# STM32C562 register map
File version: 2.1.0
CPU: CM33 r0p4, little endian, MPU, FPU, 4 interrupt priority bits
Registers are 32-bit, read-write, reset 0x0 unless marked. A register's access mark holds for its fields unless they carry their own. Offsets are from the block's base; [hi:lo] are bit positions; {n}, {i} and the like mark numbered series.

## ICACHE — ICACHE register block
Base 0x40030400
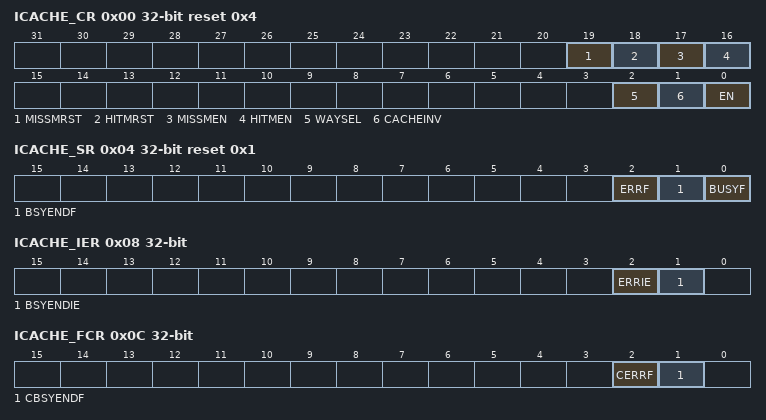
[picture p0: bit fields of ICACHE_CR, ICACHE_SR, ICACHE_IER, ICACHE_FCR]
0x00 ICACHE_CR reset 0x4 — ICACHE control register
  [19] MISSMRST — miss monitor reset
    0=release the cache miss monitor reset (needed to enable the counting); 1=reset cache miss monitor
  [18] HITMRST — hit monitor reset
    0=release the cache miss monitor reset (needed to enable the counting); 1=reset cache hit monitor
  [17] MISSMEN — miss monitor enable
    0=cache miss monitor switched off. Stopping the monitor does not reset it.; 1=cache miss monitor enabled
  [16] HITMEN — hit monitor enable
    0=cache hit monitor switched off. Stopping the monitor does not reset it.; 1=cache hit monitor enabled
  [2] WAYSEL — cache associativity mode selection
    0=direct mapped cache (1-way cache); 1=n-way set associative cache (reset value)
  [1] CACHEINV wo — cache invalidation
    0=no effect; 1=invalidate entire cache (all cache lines valid bit = 0)
  [0] EN — enable
    0=cache disabled; 1=cache enabled
0x04 ICACHE_SR ro reset 0x1 — ICACHE status register
  [2] ERRF — cache error flag
    0=no error; 1=an error occurred during the operation (cacheable write)
  [1] BSYENDF — busy end flag
    0=cache busy; 1=full invalidate CACHEINV operation finished
  [0] BUSYF — busy flag
    0=cache not busy on a CACHEINV operation; 1=cache executing a full invalidate CACHEINV operation
0x08 ICACHE_IER — ICACHE interrupt enable register
  [2] ERRIE — interrupt enable on cache error
    0=interrupt disabled on error; 1=interrupt enabled on error
  [1] BSYENDIE — interrupt enable on busy end
    0=interrupt disabled on busy end; 1=interrupt enabled on busy end
0x0C ICACHE_FCR wo — ICACHE flag clear register
  [2] CERRF — clear cache error flag
    0=no effect; 1=clears ERRF flag in ICACHE_SR
  [1] CBSYENDF — clear busy end flag
    0=no effect; 1=clears BSYENDF flag in ICACHE_SR
0x10 ICACHE_HMONR ro — ICACHE hit monitor register
  [31:0] HITMON — cache hit monitor counter
0x14 ICACHE_MMONR ro — ICACHE miss monitor register
  [15:0] MISSMON — cache miss monitor counter
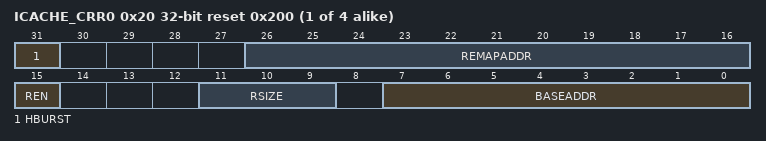
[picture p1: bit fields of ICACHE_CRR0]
{0x20+4i} ICACHE_CRR{i} reset 0x200 (i=0..3) — ICACHE region {i} configuration register
  [31] HBURST — output burst type for region x
    0=WRAP; 1=INCR
  [26:16] REMAPADDR — remapped address for region x
  [15] REN — enable for region x
    0=disabled; 1=enabled
  [11:9] RSIZE — size for region x
    1=2 Mbytes; 2=4 Mbytes; 3=8 Mbytes; 4=16 Mbytes; 5=32 Mbytes; 6=64 Mbytes; 7=128 Mbytes
  [7:0] BASEADDR — base address for region x

## PWR — PWR register block
Base 0x44020800
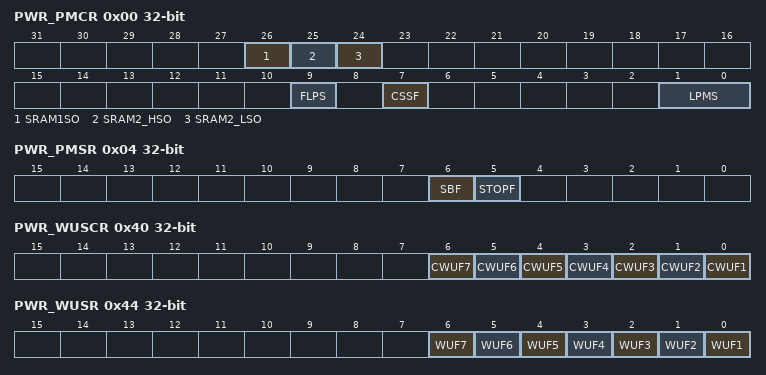
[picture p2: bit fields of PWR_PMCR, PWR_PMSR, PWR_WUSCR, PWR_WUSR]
0x00 PWR_PMCR — PWR power mode control register
  [26] SRAM1SO — AHB SRAM1 shut-off in Stop mode
    0=AHB RAM1 content is kept in Stop mode; 1=AHB RAM1 content is lost in Stop mode
  [25] SRAM2_HSO — AHB SRAM2 48-Kbyte shut-off in Stop mode (higher address)
    0=AHB RAM2 48-Kbyte content is kept in Stop mode; 1=AHB RAM2 48-Kbyte content is lost in Stop mode
  [24] SRAM2_LSO — AHB SRAM2 16-Kbyte shut-off in Stop mode (lower address)
    0=AHB RAM2 16-Kbyte content is kept in Stop mode; 1=AHB RAM2 16-Kbyte content is lost in Stop mode
  [9] FLPS — Flash memory low-power mode in Stop mode
    0=Flash memory remains in normal mode when the system enters Stop mode (quickrestart time); 1=Flash memory enters low-power mode when the system enters Stop mode(low-power consumption)
  [7] CSSF — Clear Standby and Stop flags (always read as 0)
    0=No effect; 1=STOPF and SBF flags cleared
  [1:0] LPMS — low-power mode selection
    0=Stop 0 mode when entering DeepSleep; 1=Stop 1mode when entering DeepSleep; 2=Standby mode when entering DeepSleep
0x04 PWR_PMSR ro — PWR status register
  [6] SBF — System standby flag
    0=System has not been in Standby mode; 1=System has been in Standby mode
  [5] STOPF — Stop flag
    0=System has not been in Stop mode; 1=System has been in Stop mode
0x24 PWR_RTCCR — PWR RTC domain control register
  [0] DRTCP — Disable RTC domain write protection
    0=Write access to backup domain disabled; 1=Write access to backup domain enabled
0x34 PWR_VMCR — PWR voltage monitor control register
  [0] PVDE — PVD enable
    0=PVD disabled; 1=PVD enabled
0x3C PWR_VMSR ro (reset mask 0xFF0FFFFF) — PWR voltage monitor status register
  [22] PVDO — programmable voltage detect output
    0=Vless thansub>DDless than/sub> is equal or higher than the PVD threshold; 1=Vless thansub>DDless than/sub> is lower than the PVD threshold
0x40 PWR_WUSCR wo — PWR wake-up status clear register
  [all] fields
    0=No effect; 1=Writing 1 clears the WUFx wake-up pin flag (bit is cleared to 0 by hardware)
  [n-1] CWUF{n} (n=1..7) — clear wake-up pin flag for WUFx (x=7 to 1)
0x44 PWR_WUSR ro — PWR wake-up status register
  [all] fields
    0=No wake-up event occurred; 1=Wake-up event received from WUFx pin
  [n-1] WUF{n} (n=1..7) — wake-up pin WUFx flag
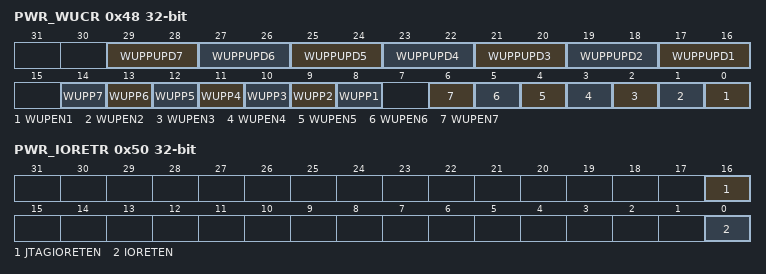
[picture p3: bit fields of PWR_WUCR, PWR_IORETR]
0x48 PWR_WUCR — PWR wake-up configuration register
  [2n+15:2n+14] WUPPUPD{n} (n=1..7) — Wake-up pin pull configuration for WKUPx (x=7to1)
    0=No pull-up; 1=Pull-up; 2=Pull-down
  [n+7] WUPP{n} (n=1..7) — Wake-up pin polarity bit for WKUPx (x=7to1)
    0=Detection on high level (rising edge); 1=Detection on low level (falling edge)
  [n-1] WUPEN{n} (n=1..7) — Enable wake-up pin WKUPx (x=7to1)
    0=An event on WUPx pin does not wake-up the system from Standby mode; 1=A rising or falling edge on WUPx pin wakes up the system from Standby mode
0x50 PWR_IORETR — PWR I/O retention register
  [16] JTAGIORETEN — IO retention enable for JTAG I/Os
    0=I/O retention mode is disabled; 1=I/O retention mode is enabling for PA13, PA14, PA15, and PB4
  [0] IORETEN — IO retention enable
    0=I/O retention mode is disabled; 1=I/O retention mode is enabling for all I/Os except the I/O support the standby functionality and PA13, PA14, PA15, and PB4
0x104 PWR_PRIVCFGR — PWR privilege configuration register
  [1] PRIV — PWR nonsecure functions privilege configuration
    0=Read and write to PWR nonsecure functions can be done by privileged or unprivileged access; 1=Read and write to PWR nonsecure functions can be done by privileged access only
